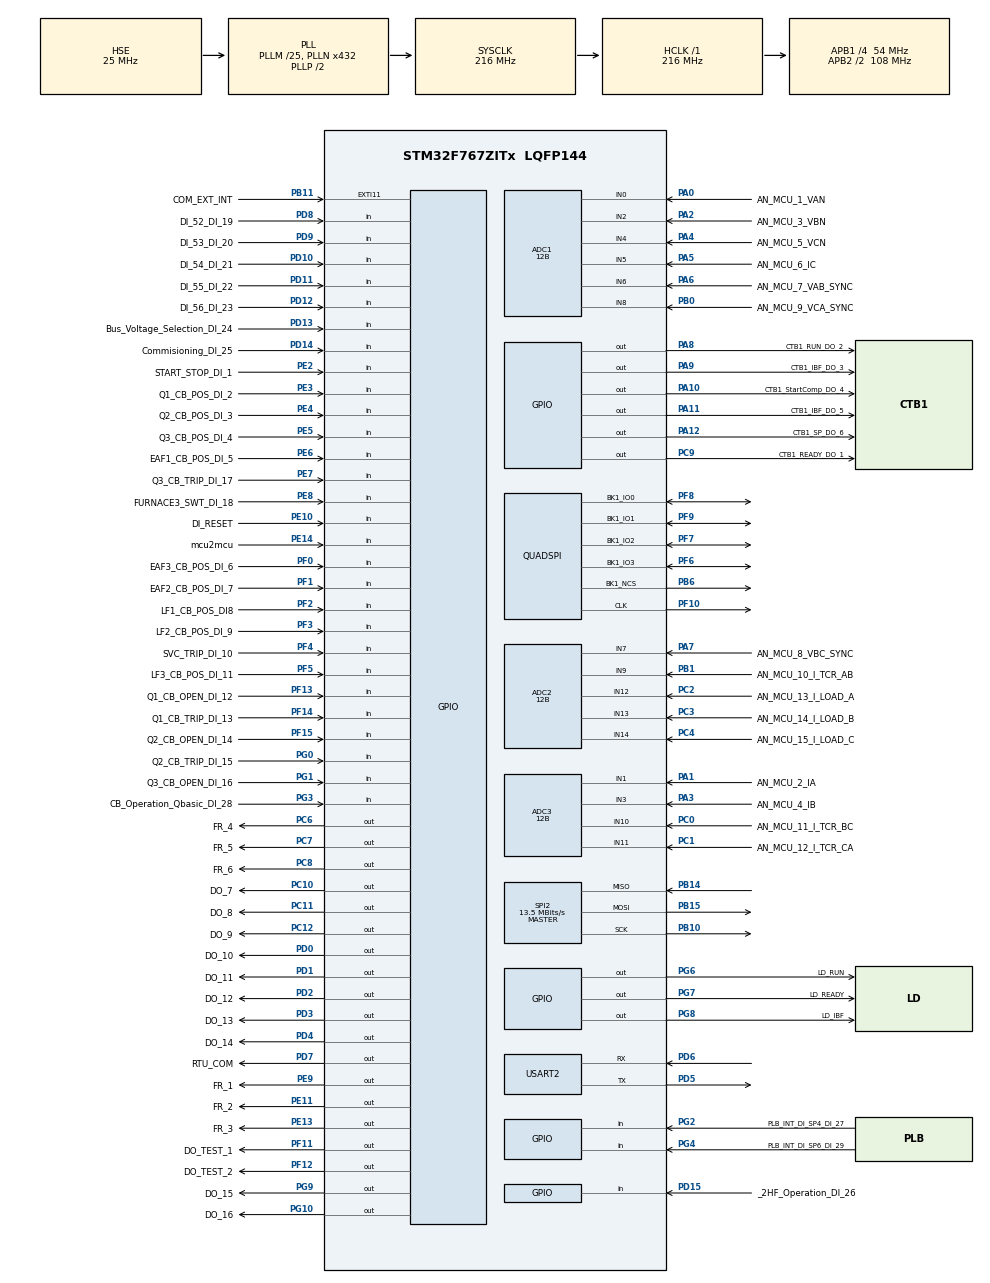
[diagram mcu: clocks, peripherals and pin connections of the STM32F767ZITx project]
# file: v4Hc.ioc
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ADC1.Channel-0\#ChannelRegularConversion=ADC_CHANNEL_0
ADC1.Channel-3\#ChannelRegularConversion=ADC_CHANNEL_2
ADC1.Channel-4\#ChannelRegularConversion=ADC_CHANNEL_4
ADC1.Channel-5\#ChannelRegularConversion=ADC_CHANNEL_5
ADC1.Channel-6\#ChannelRegularConversion=ADC_CHANNEL_6
ADC1.Channel-7\#ChannelRegularConversion=ADC_CHANNEL_8
ADC1.ClockPrescaler=ADC_CLOCK_SYNC_PCLK_DIV4
ADC1.ContinuousConvMode=DISABLE
ADC1.DMAAccessMode=ADC_DMAACCESSMODE_1
ADC1.DMAContinuousRequests=ENABLE
ADC1.DataAlign=ADC_DATAALIGN_RIGHT
ADC1.DiscontinuousConvMode=DISABLE
ADC1.EOCSelection=ADC_EOC_SEQ_CONV
ADC1.EnableAnalogWatchDog=false
ADC1.ExternalTrigConv=ADC_EXTERNALTRIGCONV_T1_TRGO
ADC1.ExternalTrigConvEdge=ADC_EXTERNALTRIGCONVEDGE_RISING
ADC1.Mode=ADC_TRIPLEMODE_REGSIMULT
ADC1.NbrOfConversion=6
ADC1.NbrOfConversionFlag=1
ADC1.Rank-0\#ChannelRegularConversion=1
ADC1.Rank-3\#ChannelRegularConversion=2
ADC1.Rank-4\#ChannelRegularConversion=3
ADC1.Rank-5\#ChannelRegularConversion=4
ADC1.Rank-6\#ChannelRegularConversion=5
ADC1.Rank-7\#ChannelRegularConversion=6
ADC1.Resolution=ADC_RESOLUTION_12B
ADC1.SamplingTime-0\#ChannelRegularConversion=ADC_SAMPLETIME_15CYCLES
ADC1.SamplingTime-3\#ChannelRegularConversion=ADC_SAMPLETIME_15CYCLES
ADC1.SamplingTime-4\#ChannelRegularConversion=ADC_SAMPLETIME_15CYCLES
ADC1.SamplingTime-5\#ChannelRegularConversion=ADC_SAMPLETIME_15CYCLES
ADC1.SamplingTime-6\#ChannelRegularConversion=ADC_SAMPLETIME_15CYCLES
ADC1.SamplingTime-7\#ChannelRegularConversion=ADC_SAMPLETIME_15CYCLES
ADC1.ScanConvMode=ENABLE
ADC1.master=1
ADC2.Channel-0\#ChannelRegularConversion=ADC_CHANNEL_12
ADC2.Channel-1\#ChannelRegularConversion=ADC_CHANNEL_13
ADC2.Channel-2\#ChannelRegularConversion=ADC_CHANNEL_14
ADC2.Channel-3\#ChannelRegularConversion=ADC_CHANNEL_9
ADC2.Channel-4\#ChannelRegularConversion=ADC_CHANNEL_7
ADC2.Channel-5\#ChannelRegularConversion=ADC_CHANNEL_9
ADC2.ClockPrescaler=ADC_CLOCK_SYNC_PCLK_DIV4
ADC2.ContinuousConvMode=DISABLE
ADC2.DMAAccessMode=ADC_DMAACCESSMODE_1
ADC2.DMAContinuousRequests=ENABLE
ADC2.DataAlign=ADC_DATAALIGN_RIGHT
ADC2.DiscontinuousConvMode=DISABLE
ADC2.EOCSelection=ADC_EOC_SEQ_CONV
ADC2.EnableAnalogWatchDog=false
ADC2.Mode=ADC_TRIPLEMODE_REGSIMULT
ADC2.NbrOfConversion=6
ADC2.NbrOfConversionFlag=1
ADC2.Rank-0\#ChannelRegularConversion=1
ADC2.Rank-1\#ChannelRegularConversion=2
ADC2.Rank-2\#ChannelRegularConversion=3
ADC2.Rank-3\#ChannelRegularConversion=4
ADC2.Rank-4\#ChannelRegularConversion=5
ADC2.Rank-5\#ChannelRegularConversion=6
ADC2.Resolution=ADC_RESOLUTION_12B
ADC2.SamplingTime-0\#ChannelRegularConversion=ADC_SAMPLETIME_15CYCLES
ADC2.SamplingTime-1\#ChannelRegularConversion=ADC_SAMPLETIME_15CYCLES
ADC2.SamplingTime-2\#ChannelRegularConversion=ADC_SAMPLETIME_15CYCLES
ADC2.SamplingTime-3\#ChannelRegularConversion=ADC_SAMPLETIME_15CYCLES
ADC2.SamplingTime-4\#ChannelRegularConversion=ADC_SAMPLETIME_15CYCLES
ADC2.SamplingTime-5\#ChannelRegularConversion=ADC_SAMPLETIME_15CYCLES
ADC2.ScanConvMode=ENABLE
ADC3.Channel-2\#ChannelRegularConversion=ADC_CHANNEL_1
ADC3.Channel-3\#ChannelRegularConversion=ADC_CHANNEL_3
ADC3.Channel-4\#ChannelRegularConversion=ADC_CHANNEL_10
ADC3.Channel-5\#ChannelRegularConversion=ADC_CHANNEL_11
ADC3.Channel-6\#ChannelRegularConversion=ADC_CHANNEL_10
ADC3.Channel-7\#ChannelRegularConversion=ADC_CHANNEL_11
ADC3.ClockPrescaler=ADC_CLOCK_SYNC_PCLK_DIV4
ADC3.ContinuousConvMode=DISABLE
ADC3.DMAAccessMode=ADC_DMAACCESSMODE_1
ADC3.DMAContinuousRequests=ENABLE
ADC3.DataAlign=ADC_DATAALIGN_RIGHT
ADC3.DiscontinuousConvMode=DISABLE
ADC3.EOCSelection=ADC_EOC_SEQ_CONV
ADC3.EnableAnalogWatchDog=false
ADC3.Mode=ADC_TRIPLEMODE_REGSIMULT
ADC3.NbrOfConversion=6
ADC3.NbrOfConversionFlag=1
ADC3.Rank-2\#ChannelRegularConversion=1
ADC3.Rank-3\#ChannelRegularConversion=2
ADC3.Rank-4\#ChannelRegularConversion=3
ADC3.Rank-5\#ChannelRegularConversion=4
ADC3.Rank-6\#ChannelRegularConversion=5
ADC3.Rank-7\#ChannelRegularConversion=6
ADC3.Resolution=ADC_RESOLUTION_12B
ADC3.SamplingTime-2\#ChannelRegularConversion=ADC_SAMPLETIME_15CYCLES
ADC3.SamplingTime-3\#ChannelRegularConversion=ADC_SAMPLETIME_15CYCLES
ADC3.SamplingTime-4\#ChannelRegularConversion=ADC_SAMPLETIME_15CYCLES
ADC3.SamplingTime-5\#ChannelRegularConversion=ADC_SAMPLETIME_15CYCLES
ADC3.SamplingTime-6\#ChannelRegularConversion=ADC_SAMPLETIME_15CYCLES
ADC3.SamplingTime-7\#ChannelRegularConversion=ADC_SAMPLETIME_15CYCLES
ADC3.ScanConvMode=ENABLE
CORTEX_M7.CPU_DCache=Enabled
CORTEX_M7.CPU_ICache=Enabled
Dma.ADC1.2.Direction=DMA_PERIPH_TO_MEMORY
Dma.ADC1.2.FIFOMode=DMA_FIFOMODE_DISABLE
Dma.ADC1.2.Instance=DMA2_Stream0
Dma.ADC1.2.MemDataAlignment=DMA_MDATAALIGN_WORD
Dma.ADC1.2.MemInc=DMA_MINC_ENABLE
Dma.ADC1.2.Mode=DMA_CIRCULAR
Dma.ADC1.2.PeriphDataAlignment=DMA_PDATAALIGN_WORD
Dma.ADC1.2.PeriphInc=DMA_PINC_DISABLE
Dma.ADC1.2.Priority=DMA_PRIORITY_HIGH
Dma.ADC2.0.Direction=DMA_PERIPH_TO_MEMORY
Dma.ADC2.0.FIFOMode=DMA_FIFOMODE_DISABLE
Dma.ADC2.0.Instance=DMA2_Stream2
Dma.ADC2.0.MemDataAlignment=DMA_MDATAALIGN_WORD
Dma.ADC2.0.MemInc=DMA_MINC_ENABLE
Dma.ADC2.0.Mode=DMA_CIRCULAR
Dma.ADC2.0.PeriphDataAlignment=DMA_PDATAALIGN_WORD
Dma.ADC2.0.PeriphInc=DMA_PINC_DISABLE
Dma.ADC2.0.Priority=DMA_PRIORITY_HIGH
Dma.ADC3.1.Direction=DMA_PERIPH_TO_MEMORY
Dma.ADC3.1.FIFOMode=DMA_FIFOMODE_DISABLE
Dma.ADC3.1.Instance=DMA2_Stream1
Dma.ADC3.1.MemDataAlignment=DMA_MDATAALIGN_WORD
Dma.ADC3.1.MemInc=DMA_MINC_ENABLE
Dma.ADC3.1.Mode=DMA_CIRCULAR
Dma.ADC3.1.PeriphDataAlignment=DMA_PDATAALIGN_WORD
Dma.ADC3.1.PeriphInc=DMA_PINC_DISABLE
Dma.ADC3.1.Priority=DMA_PRIORITY_HIGH
Dma.Request0=ADC2
Dma.Request1=ADC3
Dma.Request2=ADC1
Mcu.Family=STM32F7
Mcu.Name=STM32F767ZITx
Mcu.Package=LQFP144
NVIC.DMA2_Stream0_IRQn=true\:0\:0\:false\:true\:true\:1\:false
NVIC.DMA2_Stream1_IRQn=true\:0\:0\:false\:false\:true\:false
NVIC.DMA2_Stream2_IRQn=true\:0\:0\:false\:true\:true\:2\:false
NVIC.EXTI15_10_IRQn=true\:0\:0\:false\:false\:true\:true
NVIC.PriorityGroup=NVIC_PRIORITYGROUP_4
NVIC.SPI2_IRQn=true\:0\:0\:false\:false\:true\:true
NVIC.TIM1_UP_TIM10_IRQn=true\:0\:0\:false\:false\:true\:true
NVIC.USART2_IRQn=true\:0\:0\:false\:false\:true\:true
PA0/WKUP.GPIO_Label=AN_MCU_1_VAN
PA0/WKUP.Signal=ADCx_IN0
PA1.GPIO_Label=AN_MCU_2_IA
PA1.Signal=ADCx_IN1
PA10.GPIO_Label=CTB1_StartComp_DO_4
PA10.Signal=GPIO_Output
PA11.GPIO_Label=CTB1_IBF_DO_5
PA11.Signal=GPIO_Output
PA12.GPIO_Label=CTB1_SP_DO_6
PA12.Signal=GPIO_Output
PA13.Mode=JTAG_5_pins
PA13.Signal=SYS_JTMS-SWDIO
PA14.Mode=JTAG_5_pins
PA14.Signal=SYS_JTCK-SWCLK
PA15.Mode=JTAG_5_pins
PA15.Signal=SYS_JTDI
PA2.GPIO_Label=AN_MCU_3_VBN
PA2.Signal=ADCx_IN2
PA3.GPIO_Label=AN_MCU_4_IB
PA3.Signal=ADCx_IN3
PA4.GPIO_Label=AN_MCU_5_VCN
PA4.Signal=ADCx_IN4
PA5.GPIO_Label=AN_MCU_6_IC
PA5.Signal=ADCx_IN5
PA6.GPIO_Label=AN_MCU_7_VAB_SYNC
PA6.Signal=ADCx_IN6
PA7.GPIO_Label=AN_MCU_8_VBC_SYNC
PA7.Signal=ADCx_IN7
PA8.GPIO_Label=CTB1_RUN_DO_2
PA8.Signal=GPIO_Output
PA9.GPIO_Label=CTB1_IBF_DO_3
PA9.Signal=GPIO_Output
PB0.GPIO_Label=AN_MCU_9_VCA_SYNC
PB0.Signal=ADCx_IN8
PB1.GPIO_Label=AN_MCU_10_I_TCR_AB
PB1.Signal=ADCx_IN9
PB10.GPIO_Speed=GPIO_SPEED_FREQ_MEDIUM
PB10.Mode=Full_Duplex_Master
PB10.Signal=SPI2_SCK
PB11.GPIO_Label=COM_EXT_INT
PB11.GPIO_PuPd=GPIO_PULLDOWN
PB11.Signal=GPXTI11
PB14.GPIO_Speed=GPIO_SPEED_FREQ_MEDIUM
PB14.Mode=Full_Duplex_Master
PB14.Signal=SPI2_MISO
PB15.GPIO_Speed=GPIO_SPEED_FREQ_MEDIUM
PB15.Mode=Full_Duplex_Master
PB15.Signal=SPI2_MOSI
PB3.Mode=JTAG_5_pins
PB3.Signal=SYS_JTDO-SWO
PB4.Mode=JTAG_5_pins
PB4.Signal=SYS_JTRST
PB6.Mode=Single Bank 1
PB6.Signal=QUADSPI_BK1_NCS
PC0.GPIO_Label=AN_MCU_11_I_TCR_BC
PC0.Signal=ADCx_IN10
PC1.GPIO_Label=AN_MCU_12_I_TCR_CA
PC1.Signal=ADCx_IN11
PC10.GPIO_Label=DO_7
PC10.Signal=GPIO_Output
PC11.GPIO_Label=DO_8
PC11.Signal=GPIO_Output
PC12.GPIO_Label=DO_9
PC12.Signal=GPIO_Output
PC2.GPIO_Label=AN_MCU_13_I_LOAD_A
PC2.Signal=ADCx_IN12
PC3.GPIO_Label=AN_MCU_14_I_LOAD_B
PC3.Signal=ADCx_IN13
PC4.GPIO_Label=AN_MCU_15_I_LOAD_C
PC4.Signal=ADCx_IN14
PC6.GPIO_Label=FR_4
PC6.Signal=GPIO_Output
PC7.GPIO_Label=FR_5
PC7.Signal=GPIO_Output
PC8.GPIO_Label=FR_6
PC8.Signal=GPIO_Output
PC9.GPIO_Label=CTB1_READY_DO_1
PC9.Signal=GPIO_Output
PD0.GPIO_Label=DO_10
PD0.Signal=GPIO_Output
PD1.GPIO_Label=DO_11
PD1.Signal=GPIO_Output
PD10.GPIO_Label=DI_54_DI_21
PD10.Signal=GPIO_Input
PD11.GPIO_Label=DI_55_DI_22
PD11.Signal=GPIO_Input
PD12.GPIO_Label=DI_56_DI_23
PD12.Signal=GPIO_Input
PD13.GPIO_Label=Bus_Voltage_Selection_DI_24
PD13.Signal=GPIO_Input
PD14.GPIO_Label=Commisioning_DI_25
PD14.Signal=GPIO_Input
PD15.GPIO_Label=_2HF_Operation_DI_26
PD15.Signal=GPIO_Input
PD2.GPIO_Label=DO_12
PD2.Signal=GPIO_Output
PD3.GPIO_Label=DO_13
PD3.Signal=GPIO_Output
PD4.GPIO_Label=DO_14
PD4.Signal=GPIO_Output
PD5.GPIO_Speed=GPIO_SPEED_FREQ_MEDIUM
PD5.Mode=Asynchronous
PD5.Signal=USART2_TX
PD6.GPIO_Speed=GPIO_SPEED_FREQ_MEDIUM
PD6.Mode=Asynchronous
PD6.Signal=USART2_RX
PD7.GPIO_Label=RTU_COM
PD7.Signal=GPIO_Output
PD8.GPIO_Label=DI_52_DI_19
PD8.Signal=GPIO_Input
PD9.GPIO_Label=DI_53_DI_20
PD9.Signal=GPIO_Input
PE10.GPIO_Label=DI_RESET
PE10.Signal=GPIO_Input
PE11.GPIO_Label=FR_2
PE11.Signal=GPIO_Output
PE13.GPIO_Label=FR_3
PE13.Signal=GPIO_Output
PE14.GPIO_Label=mcu2mcu
PE14.Signal=GPIO_Input
PE2.GPIO_Label=START_STOP_DI_1
PE2.Signal=GPIO_Input
PE3.GPIO_Label=Q1_CB_POS_DI_2
PE3.Signal=GPIO_Input
PE4.GPIO_Label=Q2_CB_POS_DI_3
PE4.Signal=GPIO_Input
PE5.GPIO_Label=Q3_CB_POS_DI_4
PE5.Signal=GPIO_Input
PE6.GPIO_Label=EAF1_CB_POS_DI_5
PE6.Signal=GPIO_Input
PE7.GPIO_Label=Q3_CB_TRIP_DI_17
PE7.Signal=GPIO_Input
PE8.GPIO_Label=FURNACE3_SWT_DI_18
PE8.Signal=GPIO_Input
PE9.GPIO_Label=FR_1
PE9.Signal=GPIO_Output
PF0.GPIO_Label=EAF3_CB_POS_DI_6
PF0.Signal=GPIO_Input
PF1.GPIO_Label=EAF2_CB_POS_DI_7
PF1.Signal=GPIO_Input
PF10.GPIO_Speed=GPIO_SPEED_FREQ_MEDIUM
PF10.Mode=Single Bank 1
PF10.Signal=QUADSPI_CLK
PF11.GPIO_Label=DO_TEST_1
PF11.Signal=GPIO_Output
PF12.GPIO_Label=DO_TEST_2
PF12.Signal=GPIO_Output
PF13.GPIO_Label=Q1_CB_OPEN_DI_12
PF13.Signal=GPIO_Input
PF14.GPIO_Label=Q1_CB_TRIP_DI_13
PF14.Signal=GPIO_Input
PF15.GPIO_Label=Q2_CB_OPEN_DI_14
PF15.Signal=GPIO_Input
PF2.GPIO_Label=LF1_CB_POS_DI8
PF2.Signal=GPIO_Input
PF3.GPIO_Label=LF2_CB_POS_DI_9
PF3.Signal=GPIO_Input
PF4.GPIO_Label=SVC_TRIP_DI_10
PF4.Signal=GPIO_Input
PF5.GPIO_Label=LF3_CB_POS_DI_11
PF5.Signal=GPIO_Input
PF6.GPIO_Speed=GPIO_SPEED_FREQ_MEDIUM
PF6.Mode=Single Bank 1
PF6.Signal=QUADSPI_BK1_IO3
PF7.GPIO_Speed=GPIO_SPEED_FREQ_MEDIUM
PF7.Mode=Single Bank 1
PF7.Signal=QUADSPI_BK1_IO2
PF8.GPIO_Speed=GPIO_SPEED_FREQ_MEDIUM
PF8.Mode=Single Bank 1
PF8.Signal=QUADSPI_BK1_IO0
PF9.GPIO_Speed=GPIO_SPEED_FREQ_MEDIUM
PF9.Mode=Single Bank 1
PF9.Signal=QUADSPI_BK1_IO1
PG0.GPIO_Label=Q2_CB_TRIP_DI_15
PG0.Signal=GPIO_Input
PG1.GPIO_Label=Q3_CB_OPEN_DI_16
PG1.Signal=GPIO_Input
PG10.GPIO_Label=DO_16
PG10.Signal=GPIO_Output
PG2.GPIO_Label=PLB_INT_DI_SP4_DI_27
PG2.Signal=GPIO_Input
PG3.GPIO_Label=CB_Operation_Qbasic_DI_28
PG3.Signal=GPIO_Input
PG4.GPIO_Label=PLB_INT_DI_SP6_DI_29
PG4.Signal=GPIO_Input
PG6.GPIO_Label=LD_RUN
PG6.Signal=GPIO_Output
PG7.GPIO_Label=LD_READY
PG7.Signal=GPIO_Output
PG8.GPIO_Label=LD_IBF
PG8.Signal=GPIO_Output
PG9.GPIO_Label=DO_15
PG9.Signal=GPIO_Output
PH0/OSC_IN.Mode=HSE-External-Oscillator
PH0/OSC_IN.Signal=RCC_OSC_IN
PH1/OSC_OUT.Mode=HSE-External-Oscillator
PH1/OSC_OUT.Signal=RCC_OSC_OUT
ProjectManager.HeapSize=0x2000
ProjectManager.StackSize=0x4000
ProjectManager.TargetToolchain=MDK-ARM V5
RCC.AHBFreq_Value=216000000
RCC.APB1CLKDivider=RCC_HCLK_DIV4
RCC.APB1Freq_Value=54000000
RCC.APB1TimFreq_Value=108000000
RCC.APB2CLKDivider=RCC_HCLK_DIV2
RCC.APB2Freq_Value=108000000
RCC.APB2TimFreq_Value=216000000
RCC.CortexFreq_Value=216000000
RCC.HCLKFreq_Value=216000000
RCC.HSE_VALUE=25000000
RCC.HSI_VALUE=16000000
RCC.LSE_VALUE=32768
RCC.PLLM=25
RCC.PLLN=432
RCC.PLLSourceVirtual=RCC_PLLSOURCE_HSE
RCC.SYSCLKFreq_VALUE=216000000
RCC.SYSCLKSource=RCC_SYSCLKSOURCE_PLLCLK
RCC.USBFreq_Value=216000000
RCC.VCOOutputFreq_Value=432000000
SH.ADCx_IN0.0=ADC1_IN0,IN0
SH.ADCx_IN1.0=ADC3_IN1,IN1
SH.ADCx_IN10.0=ADC3_IN10,IN10
SH.ADCx_IN11.0=ADC3_IN11,IN11
SH.ADCx_IN12.0=ADC2_IN12,IN12
SH.ADCx_IN13.0=ADC2_IN13,IN13
SH.ADCx_IN14.0=ADC2_IN14,IN14
SH.ADCx_IN2.0=ADC1_IN2,IN2
SH.ADCx_IN3.0=ADC3_IN3,IN3
SH.ADCx_IN4.0=ADC1_IN4,IN4
SH.ADCx_IN5.0=ADC1_IN5,IN5
SH.ADCx_IN6.0=ADC1_IN6,IN6
SH.ADCx_IN7.0=ADC2_IN7,IN7
SH.ADCx_IN8.0=ADC1_IN8,IN8
SH.ADCx_IN9.0=ADC2_IN9,IN9
SPI2.BaudRatePrescaler=SPI_BAUDRATEPRESCALER_4
SPI2.CalculateBaudRate=13.5 MBits/s
SPI2.DataSize=SPI_DATASIZE_8BIT
SPI2.Direction=SPI_DIRECTION_2LINES
SPI2.Mode=SPI_MODE_MASTER
SPI2.VirtualType=VM_MASTER
TIM1.Period=8639
TIM1.TIM_MasterOutputTrigger=TIM_TRGO_UPDATE
TIM1.TIM_MasterOutputTrigger2=TIM_TRGO2_RESET
TIM6.AutoReloadPreload=TIM_AUTORELOAD_PRELOAD_DISABLE
TIM6.Period=4139
USART2.VirtualMode-Asynchronous=VM_ASYNC
USART2.WordLength=WORDLENGTH_8B
VP_RTC_VS_RTC_Activate.Mode=RTC_Enabled
VP_TIM1_VS_ClockSourceINT.Mode=Internal
VP_TIM6_VS_ClockSourceINT.Mode=Enable_Timer
board=v4Hc

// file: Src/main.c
/**
  ******************************************************************************
  * File Name          : main.c
  * Description        : Main program body
  ******************************************************************************
  ** This notice applies to any and all portions of this file
  * that are not between comment pairs USER CODE BEGIN and
  * USER CODE END. Other portions of this file, whether
  * inserted by the user or by software development tools
  * are owned by their respective copyright owners.
  *
  * COPYRIGHT(c) 2018 STMicroelectronics
  *
  * Redistribution and use in source and binary forms, with or without modification,
  * are permitted provided that the following conditions are met:
  *   1. Redistributions of source code must retain the above copyright notice,
  *      this list of conditions and the following disclaimer.
  *   2. Redistributions in binary form must reproduce the above copyright notice,
  *      this list of conditions and the following disclaimer in the documentation
  *      and/or other materials provided with the distribution.
  *   3. Neither the name of STMicroelectronics nor the names of its contributors
  *      may be used to endorse or promote products derived from this software
  *      without specific prior written permission.
  *
  * THIS SOFTWARE IS PROVIDED BY THE COPYRIGHT HOLDERS AND CONTRIBUTORS "AS IS"
  * AND ANY EXPRESS OR IMPLIED WARRANTIES, INCLUDING, BUT NOT LIMITED TO, THE
  * IMPLIED WARRANTIES OF MERCHANTABILITY AND FITNESS FOR A PARTICULAR PURPOSE ARE
  * DISCLAIMED. IN NO EVENT SHALL THE COPYRIGHT HOLDER OR CONTRIBUTORS BE LIABLE
  * FOR ANY DIRECT, INDIRECT, INCIDENTAL, SPECIAL, EXEMPLARY, OR CONSEQUENTIAL
  * DAMAGES (INCLUDING, BUT NOT LIMITED TO, PROCUREMENT OF SUBSTITUTE GOODS OR
  * SERVICES; LOSS OF USE, DATA, OR PROFITS; OR BUSINESS INTERRUPTION) HOWEVER
  * CAUSED AND ON ANY THEORY OF LIABILITY, WHETHER IN CONTRACT, STRICT LIABILITY,
  * OR TORT (INCLUDING NEGLIGENCE OR OTHERWISE) ARISING IN ANY WAY OUT OF THE USE
  * OF THIS SOFTWARE, EVEN IF ADVISED OF THE POSSIBILITY OF SUCH DAMAGE.
  *
  ******************************************************************************
  */

#include "main.h"
#include "stm32f7xx_hal.h"
#include "adc.h"
#include "dma.h"
#include "quadspi.h"
#include "rtc.h"
#include "spi.h"
#include "tim.h"
#include "usart.h"
#include "gpio.h"

/* USER CODE BEGIN Includes */

#include "conversion.h"
#include "init_all.h"
#include "aux_functions.h"

#include "UART_MasterSlave.h"
#include "SPI_MasterSlave.h"
#include "CommConfig.h"

/* USER CODE END Includes */

/* USER CODE BEGIN PV */
/* Private variables ---------------------------------------------------------*/

uint8_t incoming_data_flag=0;
long incoming_data_flag_counter=0;

/* USER CODE END PV */

void SystemClock_Config(void);
static void MX_NVIC_Init(void);

/* USER CODE BEGIN PFP */
/* Private function prototypes -----------------------------------------------*/

void main_flow(void);
void init_all(void);
void pushDataToMaster(void);
void pullDataFromMaster(void);
/* USER CODE END PFP */

int main(void)
{

  /* Enable I-Cache-------------------------------------------------------------*/
  SCB_EnableICache();

  /* Enable D-Cache-------------------------------------------------------------*/
  SCB_EnableDCache();

  /* MCU Configuration----------------------------------------------------------*/

  /* Reset of all peripherals, Initializes the Flash interface and the Systick. */
  HAL_Init();

  /* Configure the system clock */
  SystemClock_Config();

  /* Initialize all configured peripherals */
  MX_GPIO_Init();
  MX_DMA_Init();
  MX_ADC1_Init();
  MX_ADC2_Init();
  MX_ADC3_Init();
  MX_SPI2_Init();
  MX_TIM1_Init();
  MX_USART2_UART_Init();
  MX_QUADSPI_Init();
  MX_RTC_Init();
  MX_TIM6_Init();

  /* Initialize interrupts */
  MX_NVIC_Init();

  /* USER CODE BEGIN 2 */

	init_all();

  /* USER CODE END 2 */

  /* Infinite loop */
  /* USER CODE BEGIN WHILE */

	HAL_TIM_Base_Start_IT(&htim1);
	HAL_ADC_Start(&hadc3);
	HAL_ADC_Start(&hadc2);
	HAL_ADCEx_MultiModeStart_DMA(&hadc1,(uint32_t*)adcBuffer, 18);

	uart_initComApp();
	spi_initComApp();

  while (1)
  {
  /* USER CODE END WHILE */

  /* USER CODE BEGIN 3 */

	uart_runComApp();
	spi_runComApp();

	if(conversion_completed){

		incoming_data_flag=off_delay(0,incoming_data_flag,12500,&incoming_data_flag_counter);
		conversion_completed=0;

	}

	if(incoming_data_flag){

		pullDataFromMaster();

	}else{

		pushDataToMaster();

	}

  }
  /* USER CODE END 3 */

}

/** System Clock Configuration
*/
void SystemClock_Config(void)
{

  RCC_OscInitTypeDef RCC_OscInitStruct;
  RCC_ClkInitTypeDef RCC_ClkInitStruct;
  RCC_PeriphCLKInitTypeDef PeriphClkInitStruct;

    /**Configure the main internal regulator output voltage
    */
  __HAL_RCC_PWR_CLK_ENABLE();

  __HAL_PWR_VOLTAGESCALING_CONFIG(PWR_REGULATOR_VOLTAGE_SCALE1);

    /**Initializes the CPU, AHB and APB busses clocks
    */
  RCC_OscInitStruct.OscillatorType = RCC_OSCILLATORTYPE_LSI|RCC_OSCILLATORTYPE_HSE;
  RCC_OscInitStruct.HSEState = RCC_HSE_ON;
  RCC_OscInitStruct.LSIState = RCC_LSI_ON;
  RCC_OscInitStruct.PLL.PLLState = RCC_PLL_ON;
  RCC_OscInitStruct.PLL.PLLSource = RCC_PLLSOURCE_HSE;
  RCC_OscInitStruct.PLL.PLLM = 25;
  RCC_OscInitStruct.PLL.PLLN = 432;
  RCC_OscInitStruct.PLL.PLLP = RCC_PLLP_DIV2;
  RCC_OscInitStruct.PLL.PLLQ = 2;
  if (HAL_RCC_OscConfig(&RCC_OscInitStruct) != HAL_OK)
  {
    _Error_Handler(__FILE__, __LINE__);
  }

    /**Activate the Over-Drive mode
    */
  if (HAL_PWREx_EnableOverDrive() != HAL_OK)
  {
    _Error_Handler(__FILE__, __LINE__);
  }

    /**Initializes the CPU, AHB and APB busses clocks
    */
  RCC_ClkInitStruct.ClockType = RCC_CLOCKTYPE_HCLK|RCC_CLOCKTYPE_SYSCLK
                              |RCC_CLOCKTYPE_PCLK1|RCC_CLOCKTYPE_PCLK2;
  RCC_ClkInitStruct.SYSCLKSource = RCC_SYSCLKSOURCE_PLLCLK;
  RCC_ClkInitStruct.AHBCLKDivider = RCC_SYSCLK_DIV1;
  RCC_ClkInitStruct.APB1CLKDivider = RCC_HCLK_DIV4;
  RCC_ClkInitStruct.APB2CLKDivider = RCC_HCLK_DIV2;

  if (HAL_RCC_ClockConfig(&RCC_ClkInitStruct, FLASH_LATENCY_7) != HAL_OK)
  {
    _Error_Handler(__FILE__, __LINE__);
  }

  PeriphClkInitStruct.PeriphClockSelection = RCC_PERIPHCLK_RTC|RCC_PERIPHCLK_USART2;
  PeriphClkInitStruct.RTCClockSelection = RCC_RTCCLKSOURCE_LSI;
  PeriphClkInitStruct.Usart2ClockSelection = RCC_USART2CLKSOURCE_PCLK1;
  if (HAL_RCCEx_PeriphCLKConfig(&PeriphClkInitStruct) != HAL_OK)
  {
    _Error_Handler(__FILE__, __LINE__);
  }

    /**Configure the Systick interrupt time
    */
  HAL_SYSTICK_Config(HAL_RCC_GetHCLKFreq()/1000);

    /**Configure the Systick
    */
  HAL_SYSTICK_CLKSourceConfig(SYSTICK_CLKSOURCE_HCLK);

  /* SysTick_IRQn interrupt configuration */
  HAL_NVIC_SetPriority(SysTick_IRQn, 0, 0);
}

/** NVIC Configuration
*/
static void MX_NVIC_Init(void)
{
  /* DMA2_Stream0_IRQn interrupt configuration */
  HAL_NVIC_SetPriority(DMA2_Stream0_IRQn, 0, 0);
  HAL_NVIC_EnableIRQ(DMA2_Stream0_IRQn);
  /* DMA2_Stream2_IRQn interrupt configuration */
  HAL_NVIC_SetPriority(DMA2_Stream2_IRQn, 0, 0);
  HAL_NVIC_EnableIRQ(DMA2_Stream2_IRQn);
}

void _Error_Handler(char * file, int line)
{
  while(1)
  {
  }
}

/************************ (C) COPYRIGHT STMicroelectronics *****END OF FILE****/
